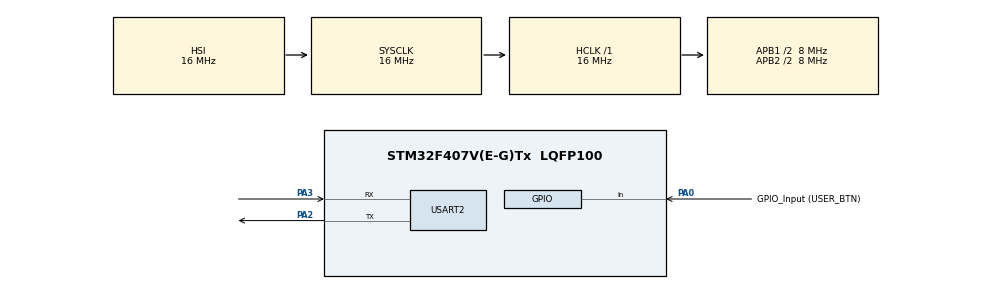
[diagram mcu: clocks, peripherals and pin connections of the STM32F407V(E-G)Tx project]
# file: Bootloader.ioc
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Mcu.Family=STM32F4
Mcu.Name=STM32F407V(E-G)Tx
Mcu.Package=LQFP100
NVIC.PriorityGroup=NVIC_PRIORITYGROUP_0
PA0-WKUP.GPIO_Label=GPIO_Input (USER_BTN) 
PA0-WKUP.Signal=GPIO_Input
PA13.Mode=Serial_Wire
PA13.Signal=SYS_JTMS-SWDIO
PA14.Mode=Serial_Wire
PA14.Signal=SYS_JTCK-SWCLK
PA2.Mode=Asynchronous
PA2.Signal=USART2_TX
PA3.Mode=Asynchronous
PA3.Signal=USART2_RX
ProjectManager.HeapSize=0x200
ProjectManager.StackSize=0x400
ProjectManager.TargetToolchain=STM32CubeIDE
RCC.48MHZClocksFreq_Value=96000000
RCC.AHBFreq_Value=16000000
RCC.APB1CLKDivider=RCC_HCLK_DIV2
RCC.APB1Freq_Value=8000000
RCC.APB1TimFreq_Value=16000000
RCC.APB2CLKDivider=RCC_HCLK_DIV2
RCC.APB2Freq_Value=8000000
RCC.APB2TimFreq_Value=16000000
RCC.CortexFreq_Value=16000000
RCC.HCLKFreq_Value=16000000
RCC.HSE_VALUE=8000000
RCC.HSI_VALUE=16000000
RCC.LSE_VALUE=32768
RCC.PLLM=8
RCC.PLLN=336
RCC.PLLQ=7
RCC.SYSCLKFreq_VALUE=16000000
RCC.VCOOutputFreq_Value=672000000
USART2.VirtualMode=VM_ASYNC
board=STM32F407G-DISC1

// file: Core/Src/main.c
/* USER CODE BEGIN Header */
/**
 ******************************************************************************
 * @file           : main.c
 * @brief          : Main program body
 ******************************************************************************
 * @attention
 *
 * Copyright (c) 2024 STMicroelectronics.
 * All rights reserved.
 *
 * This software is licensed under terms that can be found in the LICENSE file
 * in the root directory of this software component.
 * If no LICENSE file comes with this software, it is provided AS-IS.
 *
 ******************************************************************************
 */
/* USER CODE END Header */
#include "main.h"

/* USER CODE BEGIN Includes */
#include <stdint.h>
#include <stdio.h>
#include "stm32f407xx.h"

/* USER CODE END Includes */

/* USER CODE BEGIN PTD */
typedef void (*ApplicationFunc_t)(void);

/* USER CODE END PTD */

/* USER CODE BEGIN PD */
#define APPLICATION_1_OFFSET 0x8000U
#define APPLICATION_2_OFFSET 0x10000U

#define BTN_PORT GPIOA
#define BTN_PIN GPIO_PIN_0

/* USER CODE END PD */

UART_HandleTypeDef huart2;

void SystemClock_Config(void);
static void MX_GPIO_Init(void);
static void MX_USART2_UART_Init(void);

/* USER CODE BEGIN 0 */

static uint8_t ReadBtnState(void) {
	GPIO_PinState pinState = HAL_GPIO_ReadPin(BTN_PORT, BTN_PIN);
	return (pinState == GPIO_PIN_SET) ? 1U : 0U;
}

static void JumpToApp(__IO uint32_t addr) {
	uint32_t stackPtr = *(uint32_t*) addr;
	ApplicationFunc_t appFun = (ApplicationFunc_t) *((uint32_t*) (addr + 4U));
	__set_MSP(stackPtr);
	appFun();
}

/* USER CODE END 0 */

int main(void) {

	/* MCU Configuration--------------------------------------------------------*/

	/* Reset of all peripherals, Initializes the Flash interface and the Systick. */
	HAL_Init();

	/* Configure the system clock */
	SystemClock_Config();

	/* Initialize all configured peripherals */
	MX_GPIO_Init();
	MX_USART2_UART_Init();
	/* USER CODE BEGIN 2 */
	(void) printf("/************ Bootloader Started ************/\r\n");

	/* USER CODE END 2 */

	/* Infinite loop */
	while (1) {

		/* USER CODE BEGIN 3 */
		uint32_t addr = 0x00;
		if (ReadBtnState() == 1U) {
			addr = FLASH_BASE + APPLICATION_2_OFFSET;
			(void) printf("'Application 2' Selected (address : 0x%08x)\r\n",
					(unsigned int)addr);
			JumpToApp(addr);
		} else {
			addr = FLASH_BASE + APPLICATION_1_OFFSET;
			(void) printf("'Application 1' Selected (address : 0x%08x)\r\n",
					(unsigned int)addr);
			JumpToApp(addr);
		}
	}
	/* USER CODE END 3 */
}

void SystemClock_Config(void) {
	RCC_OscInitTypeDef RCC_OscInitStruct = { 0 };
	RCC_ClkInitTypeDef RCC_ClkInitStruct = { 0 };

	/** Configure the main internal regulator output voltage
	 */
	__HAL_RCC_PWR_CLK_ENABLE();
	__HAL_PWR_VOLTAGESCALING_CONFIG(PWR_REGULATOR_VOLTAGE_SCALE1);

	/** Initializes the RCC Oscillators according to the specified parameters
	 * in the RCC_OscInitTypeDef structure.
	 */
	RCC_OscInitStruct.OscillatorType = RCC_OSCILLATORTYPE_HSI;
	RCC_OscInitStruct.HSIState = RCC_HSI_ON;
	RCC_OscInitStruct.HSICalibrationValue = RCC_HSICALIBRATION_DEFAULT;
	RCC_OscInitStruct.PLL.PLLState = RCC_PLL_NONE;
	if (HAL_RCC_OscConfig(&RCC_OscInitStruct) != HAL_OK) {
		Error_Handler();
	}

	/** Initializes the CPU, AHB and APB buses clocks
	 */
	RCC_ClkInitStruct.ClockType = RCC_CLOCKTYPE_HCLK | RCC_CLOCKTYPE_SYSCLK
			| RCC_CLOCKTYPE_PCLK1 | RCC_CLOCKTYPE_PCLK2;
	RCC_ClkInitStruct.SYSCLKSource = RCC_SYSCLKSOURCE_HSI;
	RCC_ClkInitStruct.AHBCLKDivider = RCC_SYSCLK_DIV1;
	RCC_ClkInitStruct.APB1CLKDivider = RCC_HCLK_DIV2;
	RCC_ClkInitStruct.APB2CLKDivider = RCC_HCLK_DIV2;

	if (HAL_RCC_ClockConfig(&RCC_ClkInitStruct, FLASH_LATENCY_0) != HAL_OK) {
		Error_Handler();
	}
}

static void MX_USART2_UART_Init(void) {

	huart2.Instance = USART2;
	huart2.Init.BaudRate = 115200;
	huart2.Init.WordLength = UART_WORDLENGTH_8B;
	huart2.Init.StopBits = UART_STOPBITS_1;
	huart2.Init.Parity = UART_PARITY_NONE;
	huart2.Init.Mode = UART_MODE_TX_RX;
	huart2.Init.HwFlowCtl = UART_HWCONTROL_NONE;
	huart2.Init.OverSampling = UART_OVERSAMPLING_16;
	if (HAL_UART_Init(&huart2) != HAL_OK) {
		Error_Handler();
	}

}

static void MX_GPIO_Init(void) {
	GPIO_InitTypeDef GPIO_InitStruct = { 0 };

	/* GPIO Ports Clock Enable */
	__HAL_RCC_GPIOA_CLK_ENABLE();

	/*Configure GPIO pin : GPIO_Input_Pin */
	GPIO_InitStruct.Pin = GPIO_Input_Pin;
	GPIO_InitStruct.Mode = GPIO_MODE_INPUT;
	GPIO_InitStruct.Pull = GPIO_NOPULL;
	HAL_GPIO_Init(GPIO_Input_GPIO_Port, &GPIO_InitStruct);

}

/* USER CODE BEGIN 4 */

/*
 * Syscall required for 'printf()'
 */
int _write(int file, char *ptr, int len) {
	(void) file;
	int DataIdx;

	for (DataIdx = 0; DataIdx < len; DataIdx++) {
		(void) HAL_UART_Transmit(&huart2, (uint8_t*) ptr++, 1U, 100U);
	}
	return len;
}

/* USER CODE END 4 */

void Error_Handler(void) {
	__disable_irq();
	while (1) {
	}
}
